# PIC32CK2051SG01144 register map
Vendor: Microchip Technology; Series: PIC32CKSG01; File version: 0
CPU: CM33 r0p0, little endian, MPU, FPU, DSP, 3 interrupt priority bits, 158 interrupts, 23 SAU regions
Registers are 32-bit, read-write, reset 0x0 unless marked. A register's access mark holds for its fields unless they carry their own. Offsets are from the block's base; [hi:lo] are bit positions; lines under a group give offsets from that group; {n}, {i} and the like mark numbered series; 'fields as' and 'values as' point back to an identical list.

## DMA0 — Direct Memory Access Controller
Base 0x44802000; register names take the prefix DMA_
Same registers: DMA1 0x44804000
0x00 CTRLA — DMA CONTROL A REGISTER
  [1] ENABLE — DMA Enable
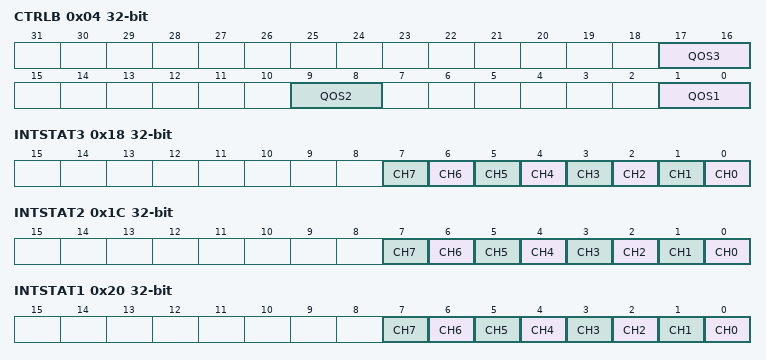
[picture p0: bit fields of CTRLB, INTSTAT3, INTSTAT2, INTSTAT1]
0x04 CTRLB — DMA CONTROL B REGISTER
  [all] fields
    0=LEVEL_0 (QoS level is 0 (lowest)); 1=LEVEL_1 (QoS level is 1 (lower)); 2=LEVEL_2 (QoS level is 2 (medium)); 3=LEVEL_3 (QoS level is 3 (high))
  [17:16] QOS3 — Priority Group 3 Quality Of Service Control
  [9:8] QOS2 — Priority Group 2 Quality Of Service Control
  [1:0] QOS1 — Priority Group 1 Quality Of Service Control
0x08 DBGCTRL — DEBUG CONTROL REGISTER
  [0] DBGRUN — Debug Run
0x0C CRCPOLYA — DMA CRC POLYNOMIAL A REGISTER
  [31:0] POLYA — CRC Polynomial Coefficients A Register
0x10 CRCPOLYB — DMA CRC POLYNOMIAL B REGISTER
  [31:0] POLYB — CRC Polynomial Coefficients B Register
0x18 INTSTAT3 ro — DMA INTERRUPT PRIORITY 3 STATUS REGISTER
  [n] CH{n} (n=0..7) — DMA Channel active interrupt at priority 3
0x1C INTSTAT2 ro — DMA INTERRUPT PRIORITY 2 STATUS REGISTER
  [n] CH{n} (n=0..7) — DMA Channel active interrupt at priority 2
0x20 INTSTAT1 ro — DMA INTERRUPT PRIORITY 1 STATUS REGISTER
  [n] CH{n} (n=0..7) — DMA Channel active interrupt at priority 1
{0x50+0x50*i} CHANNEL[{i}] (i=0..7) group
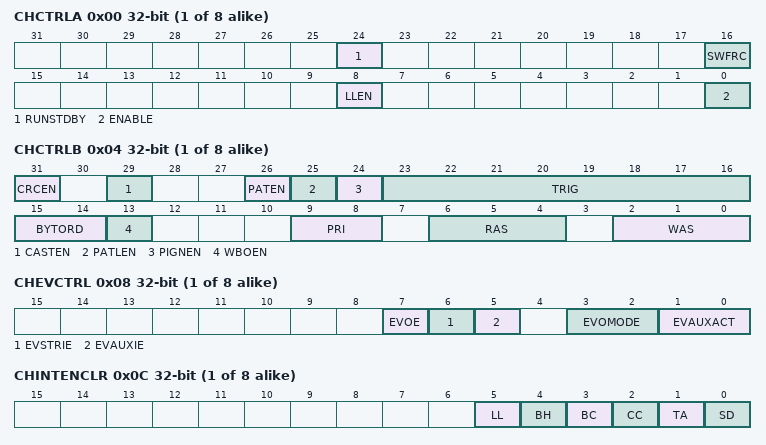
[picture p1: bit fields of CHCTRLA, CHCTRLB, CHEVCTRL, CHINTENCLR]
  0x00 CHCTRLA — CHANNEL CONTROL REGISTER A
    [24] RUNSTDBY — Run In Standby
    [16] SWFRC — Software Forced Trigger
    [8] LLEN — Linked List Enable
    [0] ENABLE — Channel Enable
  0x04 CHCTRLB — CHANNEL CONTROL REGISTER B
    [31] CRCEN — CRC Enable bit
    [29] CASTEN — Cell Auto Start Enable of Ensuing Transfers for this channel
    [26] PATEN — Channel Pattern Match Abort Enable.
    [25] PATLEN — Pattern Match Length
    [24] PIGNEN — Enable Pattern Ignore Byte
    [23:16] TRIG — Trigger that can Start a Channel Transfer
    [15:14] BYTORD — Byte Order
      0=BYTORD_NONE (Bytes are processed AS IS); 1=BYTORD_WORD_SWIZZLE (Bytes are swapped as: BYTE3 to BYTE0, BYTE2 to BYTE1, BYTE1 to BYTE2, and BYTE0 to BYTE3); 2=BYTORD_HALF_WORD_SWIZZLE (Bytes are swapped as: BYTE3 to BYTE1, BYTE2 to BYTE0, BYTE1 to BYTE3, and BYTE0 to BYTE2); 3=BYTORD_BYTE_SWIZZLE (Bytes are swapped as: BYTE3 to BYTE2, BYTE2 to BYTE3, BYTE1 to BYTE0, and BYTE0 to BYTE1)
    [13] WBOEN — Write Byte Order Enable
    [9:8] PRI — Channel Priority level.
      0=Channel Priority is 1; 1=Channel Priority is 2; 2=Channel Priority is 3 (HIGHEST)
    [6:4] RAS — Channel Read Address Sequence
      0=BYTE_ADDR_INCR (Incrementing Address+1 with Transfers of Byte Operands); 1=HALF_WORD_ADDR_INCR (Incrementing Address+2 with Transfers of HalfWord Operands); 2=AUTO_ADDR_INCR (Auto Increment Address and Transfer Size); 3=FIXED_BYTE_ADDR_INCR (Fixed Byte Address (Single Byte Address with Enable Based upon 2 LSBs)); 4=FIXED_HALF_WORD_ADDR_INCR (Fixed Address of HalfWord Operand (Single HalfWord Aligned Address)); 5=FIXED_WORD_ADDR_INCR (Fixed Address Word Burst Transfer)
    [2:0] WAS — Channel Write Address Sequence.
      values as RAS
  0x08 CHEVCTRL — CHANNEL EVENT CONTROL REGISTER
    [7] EVOE — Channel Event Output Enable (0: disable; 1: enable)
    [6] EVSTRIE — Channel Start Event Input Enable (0: disable; 1:enable)
    [5] EVAUXIE — Channel Auxiliary Event Enable (0: disable; 1: enable)
    [3:2] EVOMODE — Channel Event Output Mode
      0=STRB_ON_BLCK_XFER (Generate a channel event strobe for 1 clock cycle at the end of block transfer); 1=STRB_ON_CELL_XFER (Generate a channel event strobe for 1 clock cycle at the end of cell transfer); 2=STRB_START_EVT_TRG_TO_CELL_XFER_READ (Generate a channel event strobe from start event trigger to the completion of cell transfer read); 3=STRB_START_EVT_TRG_TO_CELL_XFER_WRITE (Generate a channel event strobe from start event trigger to the completion of cell transfer write)
    [1:0] EVAUXACT — Channel Auxiliary Event Input Action
      0=ABORT_BLK_XFER (Event Aborts Block Transfer); 1=INCR_CHN_PRI (Event Increments Channel Priority); 2=COND_TRIG (Event acts as a Conditional Trigger); 3=ABORT_LINK_LIST (Event aborts Linked List operation and Block Transfer)
  0x0C CHINTENCLR write-1-clears — CHANNEL INTERRUPT ENABLE CLEAR REGISTER
    [5] LL — Clear Linked List Done Interrupt Enable
    [4] BH — Clear Block Transfer Half Complete Interrupt Enable
    [3] BC — Clear Cell Transfer Complete Interrupt Enable
    [2] CC — Clear Cell Transfer Complete Interrupt Enable
    [1] TA — Clear Transfer Abort Interrupt Enable
    [0] SD — Channel Event Output Enable
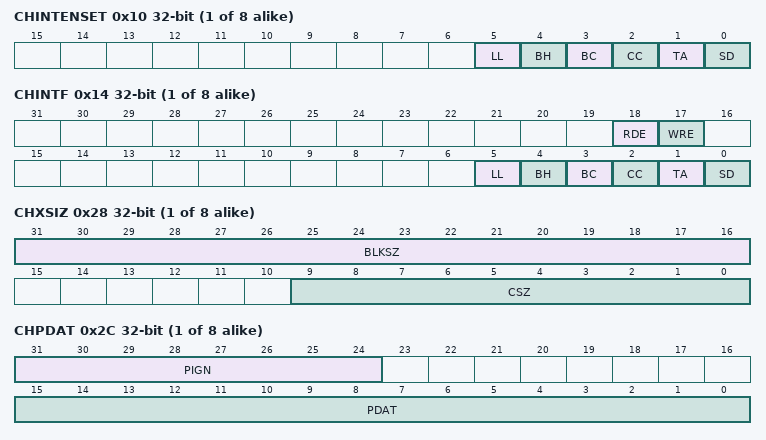
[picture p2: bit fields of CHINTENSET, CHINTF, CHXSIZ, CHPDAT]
  0x10 CHINTENSET write-1-sets — CHANNEL INTERRUPT ENABLE SET REGISTER
    [5] LL — set Linked List Done Interrupt Enable
    [4] BH — set Block Transfer Half Complete Interrupt Enable
    [3] BC — set Cell Transfer Complete Interrupt Enable
    [2] CC — set Cell Transfer Complete Interrupt Enable
    [1] TA — Set Transfer Abort Interrupt Enable
    [0] SD — Channel Event Output Enable
  0x14 CHINTF write-1-clears — CHANNEL INTERRUPT FLAG REGISTER
    [18] RDE — Read Error Flag (0: none; 1: Read Error)
    [17] WRE — Write Error Flag (0: none; 1: Write Error)
    [5] LL — Linked List Done Interrupt Flag (0: none; 1: done)
    [4] BH — Block Transfer Half Complete Interrupt Flag (0: none; 1: half complete)
    [3] BC — Block Transfer Complete Interrupt Flag (0: none; 1:complete;)
    [2] CC — Cell Transfer Complete Interrupt Flag (0: none ; 1: complete)
    [1] TA — Transfer Abort Interrupt Flag (0: none; 1: Transfer Aborted)
    [0] SD — Start Detected Interrupt Flag (0: none ; 1: Start Detected)
  0x18 CHSSA — CHANNEL SOURCE START ADDRESS
    [31:0] SSA — Channel Source Start Address
  0x1C CHDSA — CHANNEL DESTINATION START ADDRESS
    [31:0] DSA — Channel Destination Start Address
  0x20 CHSSTRD — CHANNEL SOURCE CELL STRIDE SIZE REGISTER
    [15:0] SSTRD — Source Cell Stride Size
  0x24 CHDSTRD — CHANNEL DESTINATION CELL STRIDE SIZE REGISTER
    [15:0] DSTRD — Destination Cell Stride Size
  0x28 CHXSIZ — CHANNEL TRANSFER SIZE REGISTER
    [31:16] BLKSZ — Block transfer size in bytes.
    [9:0] CSZ — Cell transfer size in bytes.
  0x2C CHPDAT — CHANNEL PATTERN MATCH DATA
    [31:24] PIGN — Channel Pattern Ignore Value
    [15:0] PDAT — Channel Pattern Match Data
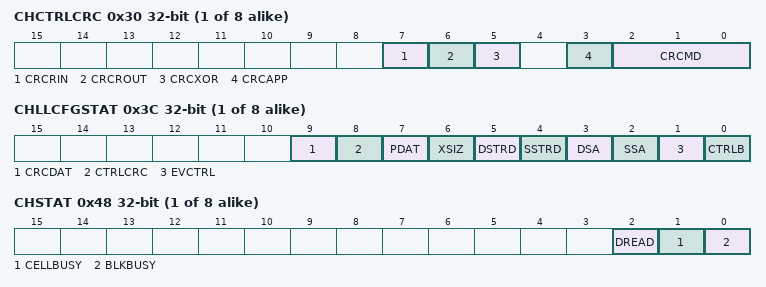
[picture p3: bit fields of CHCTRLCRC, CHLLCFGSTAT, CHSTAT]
  0x30 CHCTRLCRC — CHANNEL CONTROL CRC
    [7] CRCRIN — CRC Reflect Input Selection
    [6] CRCROUT — CRC Reflected Output Mode
    [5] CRCXOR — CRC XOR Mode
    [3] CRCAPP — CRC Append Mode
    [2:0] CRCMD — CRC/Checksum Mode
      0=CRC_16 (Normal (0x8005) CRC-16/CRC-16-IBM/CRC-16-ANSI); 1=CRC_16_CCITT (Normal (0x1021) CRC-16-CCITT); 2=16_BIT_CRCPOLYA (CRC-16 based on polynomial provided in CRCPOLYA (POLYA[15:0]) register); 3=16_BIT_CRCPOLYB (CRC-16 based on polynomial provided in CRCPOLYB (POLYB[15:0]) register); 4=CRC_32 (Normal (0x04C11DB7) CRC-32); 5=32_BIT_CRCPOLYA (CRC-32 based on polynomial provided in CRCPOLYA register); 6=32_BIT_CRCPOLYB (CRC-32 based on polynomial provided in CRCPOLYB register); 7=IP_HDR_CHECKSUM (Calculate IP header checksum)
  0x34 CHCRCDAT — CHANNEL CRC/CHECKSUM DATA REGISTER
    [31:0] CRCDAT — CRC Data
  0x38 CHNXT — CHANNEL NEXT DESCRIPTOR ADDRESS POINTER
    [31:0] NXT — Channel Address Pointer to Next Descriptor
  0x3C CHLLCFGSTAT ro — CHANNEL LINKED LIST CONFIGURATION STATUS REGISTER
    [9] CRCDAT — CRC Data Descriptor Load
    [8] CTRLCRC — Control CRC Descriptor Load
    [7] PDAT — Match Pattern Descriptor Load
    [6] XSIZ — Transfer Size Descriptor Load
    [5] DSTRD — Destination Cell Stride Size Descriptor Load
    [4] SSTRD — Source Cell Stride Size Descriptor Load
    [3] DSA — Destination Start Address Descriptor Load
    [2] SSA — Source Start Address Descriptor Load
    [1] EVCTRL — EVCTRL Register Descriptor Load
    [0] CTRLB — CTRLB Register Descriptor Load
  0x40 CHSTATBC ro — CHANNEL STATUS BLOCK COUNT REGISTER
    [16:0] BBTC — Bytes Transfered in the Block Counter
  0x44 CHSTATCC ro — CHANNEL STATUS CELL COUNT REGISTER
    [10:0] CBTC — Bytes Transfered in the Cell Counter
  0x48 CHSTAT ro — CHANNEL STATUS REGISTER
    [2] DREAD — Descriptor Read Status Bit (0: not read or not avail, 1: read and loaded)
    [1] CELLBUSY — Channel Cell Transfer Busy Status Bit (0: none; 1: busy)
    [0] BLKBUSY — Channel Block Transfer Busy Status Bit (0: none; 1: busy)

## Notices in the file
Copyright (c) 2026 Microchip Technology Inc.
SPDX-License-Identifier: Apache-2.0
Licensed under the Apache License, Version 2.0 (the "License");
you may not use this file except in compliance with the License.
You may obtain a copy of the License at
http://www.apache.org/licenses/LICENSE-2.0
Unless required by applicable law or agreed to in writing, software
distributed under the License is distributed on an "AS IS" BASIS,
WITHOUT WARRANTIES OR CONDITIONS OF ANY KIND, either express or implied.
See the License for the specific language governing permissions and
limitations under the License.
